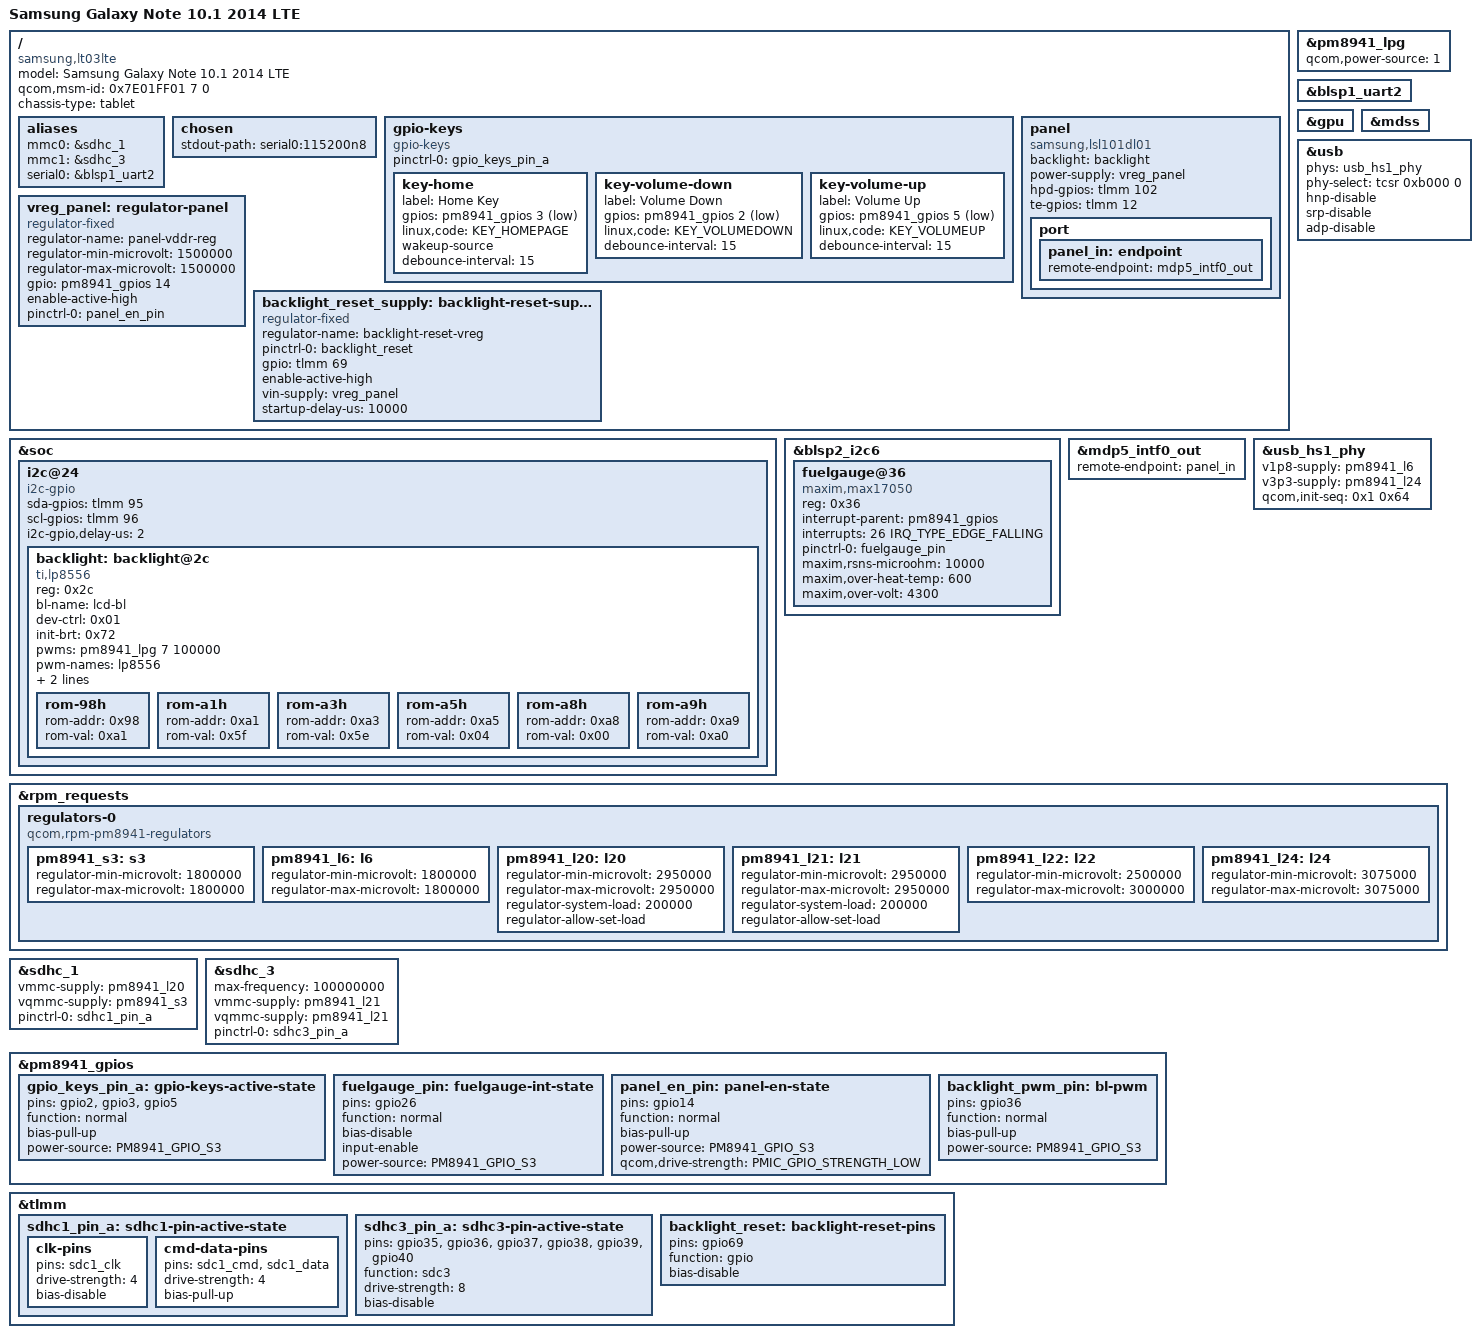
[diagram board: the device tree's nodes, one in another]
// SPDX-License-Identifier: GPL-2.0
#include "qcom-msm8974.dtsi"
#include "pm8841.dtsi"
#include "pm8941.dtsi"
#include <dt-bindings/input/input.h>
#include <dt-bindings/leds/common.h>
#include <dt-bindings/pinctrl/qcom,pmic-gpio.h>

/ {
	model = "Samsung Galaxy Note 10.1 2014 LTE";
	compatible = "samsung,lt03lte", "qcom,msm8974";
	qcom,msm-id = <0x7E01FF01 7 0>;
	chassis-type = "tablet";

	aliases {
		mmc0 = &sdhc_1; /* SDC1 eMMC slot */
		mmc1 = &sdhc_3; /* SDC3 SD card slot */
		serial0 = &blsp1_uart2;
	};

	chosen {
		stdout-path = "serial0:115200n8";
	};

	gpio-keys {
		compatible = "gpio-keys";

		pinctrl-0 = <&gpio_keys_pin_a>;
		pinctrl-names = "default";

		key-home {
			label = "Home Key";
			gpios = <&pm8941_gpios 3 GPIO_ACTIVE_LOW>;
			linux,code = <KEY_HOMEPAGE>;
			wakeup-source;
			debounce-interval = <15>;
		};

		key-volume-down {
			label = "Volume Down";
			gpios = <&pm8941_gpios 2 GPIO_ACTIVE_LOW>;
			linux,code = <KEY_VOLUMEDOWN>;
			debounce-interval = <15>;
		};

		key-volume-up {
			label = "Volume Up";
			gpios = <&pm8941_gpios 5 GPIO_ACTIVE_LOW>;
			linux,code = <KEY_VOLUMEUP>;
			debounce-interval = <15>;
		};
	};

	panel: panel {
		compatible = "samsung,lsl101dl01";

		backlight = <&backlight>;
		power-supply = <&vreg_panel>;
		hpd-gpios = <&tlmm 102 GPIO_ACTIVE_HIGH>;
		te-gpios = <&tlmm 12 GPIO_ACTIVE_HIGH>;

		port {
			panel_in: endpoint {
				remote-endpoint = <&mdp5_intf0_out>;
			};
		};
	};

	vreg_panel: regulator-panel {
		compatible = "regulator-fixed";
		regulator-name = "panel-vddr-reg";
		regulator-min-microvolt = <1500000>;
		regulator-max-microvolt = <1500000>;

		gpio = <&pm8941_gpios 14 GPIO_ACTIVE_HIGH>;
		enable-active-high;

		pinctrl-names = "default";
		pinctrl-0 = <&panel_en_pin>;
	};

	backlight_reset_supply: backlight-reset-supply {
		compatible = "regulator-fixed";
		regulator-name = "backlight-reset-vreg";
		pinctrl-names = "default";
		pinctrl-0 = <&backlight_reset>;
		gpio = <&tlmm 69 GPIO_ACTIVE_HIGH>;
		enable-active-high;
		vin-supply = <&vreg_panel>;	/* Pulls i2c pins down if not enabled */
		startup-delay-us = <10000>;
	};
};

&pm8941_lpg {
	status = "okay";

	qcom,power-source = <1>;
};

&soc {
	i2c@24 {
		compatible = "i2c-gpio";
		sda-gpios = <&tlmm 95 (GPIO_ACTIVE_HIGH|GPIO_OPEN_DRAIN)>;
		scl-gpios = <&tlmm 96 (GPIO_ACTIVE_HIGH|GPIO_OPEN_DRAIN)>;
		i2c-gpio,delay-us = <2>;
		#address-cells = <1>;
		#size-cells = <0>;

		backlight: backlight@2c {
			compatible = "ti,lp8556";
			reg = <0x2c>;

			bl-name = "lcd-bl";
			dev-ctrl = /bits/ 8 <0x01>;
			init-brt = /bits/ 8 <0x72>;	/* 114 */

			pwms = <&pm8941_lpg 7 100000>;
			pwm-names = "lp8556";
			pinctrl-names = "default";
			pinctrl-0 = <&backlight_pwm_pin>;

			enable-supply = <&backlight_reset_supply>;

			/* higher inductor current limit */
			rom-98h {
				rom-addr = /bits/ 8 <0x98>;
				rom-val = /bits/ 8 <0xa1>;
			};

			/* automatic standby via pwm disabled, 25 mA max LED current */
			rom-a1h {
				rom-addr = /bits/ 8 <0xa1>;
				rom-val = /bits/ 8 <0x5f>;
			};

			/* 200 ms slope, heavy smoothing, 1-bit PWM input hysteresis */
			rom-a3h {
				rom-addr = /bits/ 8 <0xa3>;
				rom-val = /bits/ 8 <0x5e>;
			};

			/* disable PWM passthrough, 6 PWM output phases, 9616 Hz PWM frequency */
			rom-a5h {
				rom-addr = /bits/ 8 <0xa5>;
				rom-val = /bits/ 8 <0x04>;
			};

			/* all reserved */
			rom-a8h {
				rom-addr = /bits/ 8 <0xa8>;
				rom-val = /bits/ 8 <0x00>;
			};

			/* 24 V max output voltage, jump detection on pwm input disabled */
			rom-a9h {
				rom-addr = /bits/ 8 <0xa9>;
				rom-val = /bits/ 8 <0xa0>;
			};
		};
	};
};

&blsp2_i2c6 {
	status = "okay";

	fuelgauge@36 {
		compatible = "maxim,max17050";
		reg = <0x36>;

		interrupt-parent = <&pm8941_gpios>;
		interrupts = <26 IRQ_TYPE_EDGE_FALLING>;

		pinctrl-0 = <&fuelgauge_pin>;
		pinctrl-names = "default";

		maxim,rsns-microohm = <10000>;
		maxim,over-heat-temp = <600>;
		maxim,over-volt = <4300>;
	};
};

&blsp1_uart2 {
	status = "okay";
};

&gpu {
	status = "okay";
};

&mdss {
	status = "okay";
};

&mdp5_intf0_out {
	remote-endpoint = <&panel_in>;
};

&usb {
	phys = <&usb_hs1_phy>;
	phy-select = <&tcsr 0xb000 0>;

	hnp-disable;
	srp-disable;
	adp-disable;

	status = "okay";
};

&usb_hs1_phy {
	v1p8-supply = <&pm8941_l6>;
	v3p3-supply = <&pm8941_l24>;

	qcom,init-seq = /bits/ 8 <0x1 0x64>;

	status = "okay";
};

&rpm_requests {
	regulators-0 {
		compatible = "qcom,rpm-pm8941-regulators";

		pm8941_s3: s3 {
			regulator-min-microvolt = <1800000>;
			regulator-max-microvolt = <1800000>;
		};

		pm8941_l6: l6 {
			regulator-min-microvolt = <1800000>;
			regulator-max-microvolt = <1800000>;
		};

		pm8941_l20: l20 {
			regulator-min-microvolt = <2950000>;
			regulator-max-microvolt = <2950000>;
			regulator-system-load = <200000>;
			regulator-allow-set-load;
		};

		pm8941_l21: l21 {
			regulator-min-microvolt = <2950000>;
			regulator-max-microvolt = <2950000>;
			regulator-system-load = <200000>;
			regulator-allow-set-load;
		};

		pm8941_l22: l22 {
			regulator-min-microvolt = <2500000>;
			regulator-max-microvolt = <3000000>;
		};

		pm8941_l24: l24 {
			regulator-min-microvolt = <3075000>;
			regulator-max-microvolt = <3075000>;
		};
	};
};

&sdhc_1 {
	vmmc-supply = <&pm8941_l20>;
	vqmmc-supply = <&pm8941_s3>;

	pinctrl-0 = <&sdhc1_pin_a>;
	pinctrl-names = "default";

	status = "okay";
};

&sdhc_3 {
	max-frequency = <100000000>;

	vmmc-supply = <&pm8941_l21>;
	vqmmc-supply = <&pm8941_l21>;

	pinctrl-0 = <&sdhc3_pin_a>;
	pinctrl-names = "default";

	status = "okay";
};

&pm8941_gpios {
	gpio_keys_pin_a: gpio-keys-active-state {
		pins = "gpio2", "gpio3", "gpio5";
		function = "normal";
		bias-pull-up;
		power-source = <PM8941_GPIO_S3>;
	};

	fuelgauge_pin: fuelgauge-int-state {
		pins = "gpio26";
		function = "normal";
		bias-disable;
		input-enable;
		power-source = <PM8941_GPIO_S3>;
	};

	panel_en_pin: panel-en-state {
		pins = "gpio14";
		function = "normal";
		bias-pull-up;
		power-source = <PM8941_GPIO_S3>;
		qcom,drive-strength = <PMIC_GPIO_STRENGTH_LOW>;
	};

	backlight_pwm_pin: bl-pwm {
		pins = "gpio36";
		function = "normal";
		bias-pull-up;
		power-source = <PM8941_GPIO_S3>;
	};
};

&tlmm {
	sdhc1_pin_a: sdhc1-pin-active-state {
		clk-pins {
			pins = "sdc1_clk";
			drive-strength = <4>;
			bias-disable;
		};

		cmd-data-pins {
			pins = "sdc1_cmd", "sdc1_data";
			drive-strength = <4>;
			bias-pull-up;
		};
	};

	sdhc3_pin_a: sdhc3-pin-active-state {
		pins = "gpio35", "gpio36", "gpio37", "gpio38", "gpio39", "gpio40";
		function = "sdc3";
		drive-strength = <8>;
		bias-disable;
	};

	backlight_reset: backlight-reset-pins {
		pins = "gpio69";
		function = "gpio";
		bias-disable;
	};
};
